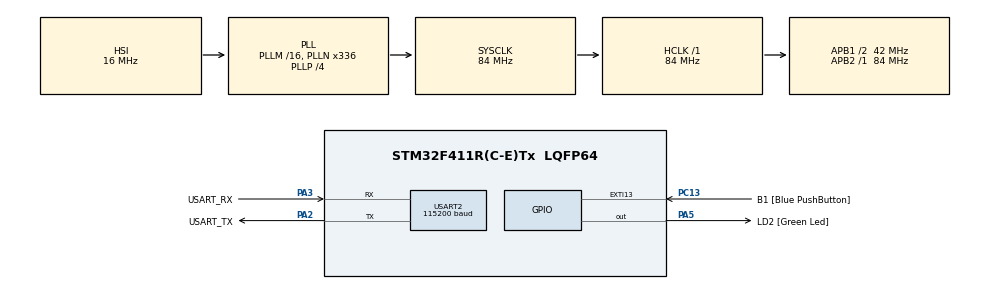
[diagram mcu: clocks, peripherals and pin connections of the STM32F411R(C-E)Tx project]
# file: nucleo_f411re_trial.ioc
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Dma.Request0=USART2_TX
Dma.USART2_TX.0.Direction=DMA_MEMORY_TO_PERIPH
Dma.USART2_TX.0.FIFOMode=DMA_FIFOMODE_DISABLE
Dma.USART2_TX.0.Instance=DMA1_Stream6
Dma.USART2_TX.0.MemDataAlignment=DMA_MDATAALIGN_BYTE
Dma.USART2_TX.0.MemInc=DMA_MINC_ENABLE
Dma.USART2_TX.0.Mode=DMA_NORMAL
Dma.USART2_TX.0.PeriphDataAlignment=DMA_PDATAALIGN_BYTE
Dma.USART2_TX.0.PeriphInc=DMA_PINC_DISABLE
Dma.USART2_TX.0.Priority=DMA_PRIORITY_LOW
FREERTOS.Queues01=uart_tx_queue,16,8,1,Static,uart_tx_queueBuffer,uart_tx_queueControlBlock
FREERTOS.Tasks01=defaultTask,24,128,StartDefaultTask,Default,NULL,Dynamic,NULL,NULL;task_uart_tx,8,256,task_uart_tx_entry,As weak,NULL,Dynamic,NULL,NULL
FREERTOS.configMINIMAL_STACK_SIZE=128
FREERTOS.configUSE_TICKLESS_IDLE=2
Mcu.Family=STM32F4
Mcu.Name=STM32F411R(C-E)Tx
Mcu.Package=LQFP64
NVIC.DMA1_Stream6_IRQn=true\:5\:0\:false\:false\:true\:true\:false\:true
NVIC.PriorityGroup=NVIC_PRIORITYGROUP_4
NVIC.TIM1_UP_TIM10_IRQn=true\:0\:0\:false\:false\:true\:false\:false\:true
NVIC.TimeBase=TIM1_UP_TIM10_IRQn
NVIC.TimeBaseIP=TIM1
NVIC.USART2_IRQn=true\:5\:0\:false\:false\:true\:true\:true\:true
PA13.GPIO_Label=TMS
PA13.Mode=Serial_Wire
PA13.Signal=SYS_JTMS-SWDIO
PA14.GPIO_Label=TCK
PA14.Mode=Serial_Wire
PA14.Signal=SYS_JTCK-SWCLK
PA2.GPIO_Label=USART_TX
PA2.Mode=Asynchronous
PA2.Signal=USART2_TX
PA3.GPIO_Label=USART_RX
PA3.Mode=Asynchronous
PA3.Signal=USART2_RX
PA5.GPIO_Label=LD2 [Green Led]
PA5.Signal=GPIO_Output
PB3.GPIO_Label=SWO
PB3.Signal=SYS_JTDO-SWO
PC13-ANTI_TAMP.GPIO_Label=B1 [Blue PushButton]
PC13-ANTI_TAMP.GPIO_ModeDefaultEXTI=GPIO_MODE_IT_FALLING
PC13-ANTI_TAMP.Signal=GPXTI13
PC14-OSC32_IN.Mode=LSE-External-Oscillator
PC14-OSC32_IN.Signal=RCC_OSC32_IN
PC15-OSC32_OUT.Mode=LSE-External-Oscillator
PC15-OSC32_OUT.Signal=RCC_OSC32_OUT
PH0\ -\ OSC_IN.Mode=HSE-External-Oscillator
PH0\ -\ OSC_IN.Signal=RCC_OSC_IN
PH1\ -\ OSC_OUT.Mode=HSE-External-Oscillator
PH1\ -\ OSC_OUT.Signal=RCC_OSC_OUT
ProjectManager.HeapSize=0x200
ProjectManager.StackSize=0x400
ProjectManager.TargetToolchain=TrueSTUDIO
RCC.48MHZClocksFreq_Value=84000000
RCC.AHBFreq_Value=84000000
RCC.APB1CLKDivider=RCC_HCLK_DIV2
RCC.APB1Freq_Value=42000000
RCC.APB1TimFreq_Value=84000000
RCC.APB2Freq_Value=84000000
RCC.APB2TimFreq_Value=84000000
RCC.CortexFreq_Value=84000000
RCC.FLatency-AdvancedSettings=FLASH_LATENCY_2
RCC.HCLKFreq_Value=84000000
RCC.HSE_VALUE=8000000
RCC.HSI_VALUE=16000000
RCC.PLLN=336
RCC.PLLP=RCC_PLLP_DIV4
RCC.SYSCLKFreq_VALUE=84000000
RCC.SYSCLKSource=RCC_SYSCLKSOURCE_PLLCLK
RCC.VCOOutputFreq_Value=336000000
USART2.BaudRate=115200
USART2.OverSampling=UART_OVERSAMPLING_16
USART2.VirtualMode=VM_ASYNC
VP_FREERTOS_VS_CMSIS_V2.Mode=CMSIS_V2
VP_SYS_VS_tim1.Mode=TIM1
board=NUCLEO-F411RE

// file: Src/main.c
/* USER CODE BEGIN Header */
/**
  ******************************************************************************
  * @file           : main.c
  * @brief          : Main program body
  ******************************************************************************
  * @attention
  *
  * <h2><center>&copy; Copyright (c) 2019 STMicroelectronics.
  * All rights reserved.</center></h2>
  *
  * This software component is licensed by ST under Ultimate Liberty license
  * SLA0044, the "License"; You may not use this file except in compliance with
  * the License. You may obtain a copy of the License at:
  *                             www.st.com/SLA0044
  *
  ******************************************************************************
  */
/* USER CODE END Header */

#include "main.h"
#include "cmsis_os.h"

/* USER CODE BEGIN Includes */
#include "string.h"
#include "uart_tx.h"
/* USER CODE END Includes */

UART_HandleTypeDef huart2;
DMA_HandleTypeDef hdma_usart2_tx;

typedef StaticQueue_t osStaticMessageQDef_t;
osThreadId_t defaultTaskHandle;
osThreadId_t task_uart_txHandle;
osMessageQueueId_t uart_tx_queueHandle;
uint8_t uart_tx_queueBuffer[ 16 * 8 ];
osStaticMessageQDef_t uart_tx_queueControlBlock;

void SystemClock_Config(void);
static void MX_GPIO_Init(void);
static void MX_DMA_Init(void);
static void MX_USART2_UART_Init(void);
void StartDefaultTask(void *argument);
void task_uart_tx_entry(void *argument);

int main(void)
{

  /* MCU Configuration--------------------------------------------------------*/

  /* Reset of all peripherals, Initializes the Flash interface and the Systick. */
  HAL_Init();

  /* Configure the system clock */
  SystemClock_Config();

  /* Initialize all configured peripherals */
  MX_GPIO_Init();
  MX_DMA_Init();
  MX_USART2_UART_Init();

  osKernelInitialize();

  /* Create the queue(s) */
  /* definition and creation of uart_tx_queue */
  const osMessageQueueAttr_t uart_tx_queue_attributes = {
    .name = "uart_tx_queue",
    .cb_mem = &uart_tx_queueControlBlock,
    .cb_size = sizeof(uart_tx_queueControlBlock),
    .mq_mem = &uart_tx_queueBuffer,
    .mq_size = sizeof(uart_tx_queueBuffer)
  };
  uart_tx_queueHandle = osMessageQueueNew (16, 8, &uart_tx_queue_attributes);

  /* Create the thread(s) */
  /* definition and creation of defaultTask */
  const osThreadAttr_t defaultTask_attributes = {
    .name = "defaultTask",
    .priority = (osPriority_t) osPriorityNormal,
    .stack_size = 128
  };
  defaultTaskHandle = osThreadNew(StartDefaultTask, NULL, &defaultTask_attributes);

  /* definition and creation of task_uart_tx */
  const osThreadAttr_t task_uart_tx_attributes = {
    .name = "task_uart_tx",
    .priority = (osPriority_t) osPriorityLow,
    .stack_size = 256
  };
  task_uart_txHandle = osThreadNew(task_uart_tx_entry, NULL, &task_uart_tx_attributes);

  /* Start scheduler */
  osKernelStart();

  /* We should never get here as control is now taken by the scheduler */

  /* Infinite loop */
  while (1)
  {

  }
}

void SystemClock_Config(void)
{
  RCC_OscInitTypeDef RCC_OscInitStruct = {0};
  RCC_ClkInitTypeDef RCC_ClkInitStruct = {0};

  /** Configure the main internal regulator output voltage
  */
  __HAL_RCC_PWR_CLK_ENABLE();
  __HAL_PWR_VOLTAGESCALING_CONFIG(PWR_REGULATOR_VOLTAGE_SCALE1);
  /** Initializes the CPU, AHB and APB busses clocks
  */
  RCC_OscInitStruct.OscillatorType = RCC_OSCILLATORTYPE_HSI;
  RCC_OscInitStruct.HSIState = RCC_HSI_ON;
  RCC_OscInitStruct.HSICalibrationValue = RCC_HSICALIBRATION_DEFAULT;
  RCC_OscInitStruct.PLL.PLLState = RCC_PLL_ON;
  RCC_OscInitStruct.PLL.PLLSource = RCC_PLLSOURCE_HSI;
  RCC_OscInitStruct.PLL.PLLM = 16;
  RCC_OscInitStruct.PLL.PLLN = 336;
  RCC_OscInitStruct.PLL.PLLP = RCC_PLLP_DIV4;
  RCC_OscInitStruct.PLL.PLLQ = 4;
  if (HAL_RCC_OscConfig(&RCC_OscInitStruct) != HAL_OK)
  {
    Error_Handler();
  }
  /** Initializes the CPU, AHB and APB busses clocks
  */
  RCC_ClkInitStruct.ClockType = RCC_CLOCKTYPE_HCLK|RCC_CLOCKTYPE_SYSCLK
                              |RCC_CLOCKTYPE_PCLK1|RCC_CLOCKTYPE_PCLK2;
  RCC_ClkInitStruct.SYSCLKSource = RCC_SYSCLKSOURCE_PLLCLK;
  RCC_ClkInitStruct.AHBCLKDivider = RCC_SYSCLK_DIV1;
  RCC_ClkInitStruct.APB1CLKDivider = RCC_HCLK_DIV2;
  RCC_ClkInitStruct.APB2CLKDivider = RCC_HCLK_DIV1;

  if (HAL_RCC_ClockConfig(&RCC_ClkInitStruct, FLASH_LATENCY_2) != HAL_OK)
  {
    Error_Handler();
  }
}

static void MX_USART2_UART_Init(void)
{

  huart2.Instance = USART2;
  huart2.Init.BaudRate = 115200;
  huart2.Init.WordLength = UART_WORDLENGTH_8B;
  huart2.Init.StopBits = UART_STOPBITS_1;
  huart2.Init.Parity = UART_PARITY_NONE;
  huart2.Init.Mode = UART_MODE_TX_RX;
  huart2.Init.HwFlowCtl = UART_HWCONTROL_NONE;
  huart2.Init.OverSampling = UART_OVERSAMPLING_16;
  if (HAL_UART_Init(&huart2) != HAL_OK)
  {
    Error_Handler();
  }

}

static void MX_DMA_Init(void)
{

  /* DMA controller clock enable */
  __HAL_RCC_DMA1_CLK_ENABLE();

  /* DMA interrupt init */
  /* DMA1_Stream6_IRQn interrupt configuration */
  HAL_NVIC_SetPriority(DMA1_Stream6_IRQn, 5, 0);
  HAL_NVIC_EnableIRQ(DMA1_Stream6_IRQn);

}

static void MX_GPIO_Init(void)
{
  GPIO_InitTypeDef GPIO_InitStruct = {0};

  /* GPIO Ports Clock Enable */
  __HAL_RCC_GPIOC_CLK_ENABLE();
  __HAL_RCC_GPIOH_CLK_ENABLE();
  __HAL_RCC_GPIOA_CLK_ENABLE();
  __HAL_RCC_GPIOB_CLK_ENABLE();

  /*Configure GPIO pin Output Level */
  HAL_GPIO_WritePin(LD2_GPIO_Port, LD2_Pin, GPIO_PIN_RESET);

  /*Configure GPIO pin : B1_Pin */
  GPIO_InitStruct.Pin = B1_Pin;
  GPIO_InitStruct.Mode = GPIO_MODE_IT_FALLING;
  GPIO_InitStruct.Pull = GPIO_NOPULL;
  HAL_GPIO_Init(B1_GPIO_Port, &GPIO_InitStruct);

  /*Configure GPIO pin : LD2_Pin */
  GPIO_InitStruct.Pin = LD2_Pin;
  GPIO_InitStruct.Mode = GPIO_MODE_OUTPUT_PP;
  GPIO_InitStruct.Pull = GPIO_NOPULL;
  GPIO_InitStruct.Speed = GPIO_SPEED_FREQ_LOW;
  HAL_GPIO_Init(LD2_GPIO_Port, &GPIO_InitStruct);

}

void StartDefaultTask(void *argument)
{

  /* USER CODE BEGIN 5 */
  /* Infinite loop */
  char *template = "I'm QQM123\r\n";
  for(;;)
  {
    //extern void uart_tx_send_str(char *str);
    //uart_tx_send_str(template);

    extern void uart_tx_send_str_pkt(char *str);
    uart_tx_send_str_pkt(template);

    osDelay(3);
  }
  /* USER CODE END 5 */
}

__weak void task_uart_tx_entry(void *argument)
{
  for(;;)
  {
    osDelay(1);
  }
}

void HAL_TIM_PeriodElapsedCallback(TIM_HandleTypeDef *htim)
{
  if (htim->Instance == TIM1) {
    HAL_IncTick();
  }
}

void Error_Handler(void)
{
}

/************************ (C) COPYRIGHT STMicroelectronics *****END OF FILE****/

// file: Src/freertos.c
/* USER CODE BEGIN Header */
/**
  ******************************************************************************
  * File Name          : freertos.c
  * Description        : Code for freertos applications
  ******************************************************************************
  * @attention
  *
  * <h2><center>&copy; Copyright (c) 2019 STMicroelectronics.
  * All rights reserved.</center></h2>
  *
  * This software component is licensed by ST under Ultimate Liberty license
  * SLA0044, the "License"; You may not use this file except in compliance with
  * the License. You may obtain a copy of the License at:
  *                             www.st.com/SLA0044
  *
  ******************************************************************************
  */
/* USER CODE END Header */

#include "FreeRTOS.h"
#include "task.h"
#include "main.h"

/* USER CODE BEGIN VPORT_SUPPORT_TICKS_AND_SLEEP */
__weak void vPortSuppressTicksAndSleep( TickType_t xExpectedIdleTime )
{
  // Generated when configUSE_TICKLESS_IDLE == 2.
  // Function called in tasks.c (in portTASK_FUNCTION).
  // TO BE COMPLETED or TO BE REPLACED by a user one, overriding that weak one.
}
/* USER CODE END VPORT_SUPPORT_TICKS_AND_SLEEP */

/************************ (C) COPYRIGHT STMicroelectronics *****END OF FILE****/
